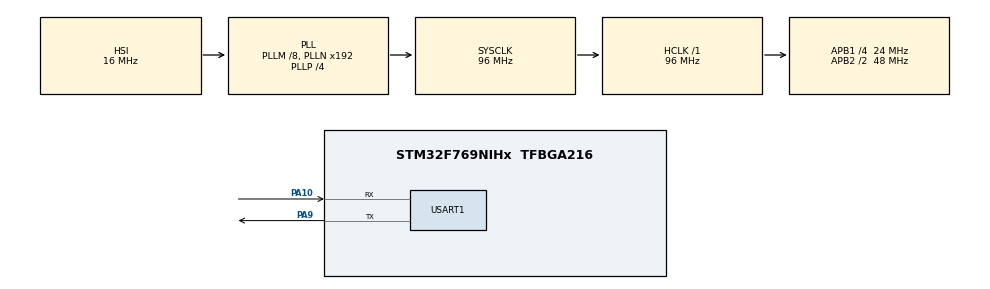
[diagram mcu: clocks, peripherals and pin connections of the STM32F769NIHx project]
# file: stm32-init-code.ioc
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Mcu.Family=STM32F7
Mcu.Name=STM32F769NIHx
Mcu.Package=TFBGA216
NVIC.PriorityGroup=NVIC_PRIORITYGROUP_4
PA10.Mode=Asynchronous
PA10.Signal=USART1_RX
PA9.Mode=Asynchronous
PA9.Signal=USART1_TX
ProjectManager.HeapSize=0x200
ProjectManager.StackSize=0x400
ProjectManager.TargetToolchain=Makefile
RCC.AHBFreq_Value=96000000
RCC.APB1CLKDivider=RCC_HCLK_DIV4
RCC.APB1Freq_Value=24000000
RCC.APB1TimFreq_Value=48000000
RCC.APB2CLKDivider=RCC_HCLK_DIV2
RCC.APB2Freq_Value=48000000
RCC.APB2TimFreq_Value=96000000
RCC.CortexFreq_Value=96000000
RCC.HCLKFreq_Value=96000000
RCC.HSE_VALUE=25000000
RCC.HSI_VALUE=16000000
RCC.LSE_VALUE=32768
RCC.PLLM=8
RCC.PLLP=RCC_PLLP_DIV4
RCC.PLLQ=4
RCC.PLLSAIQ=3
RCC.SYSCLKFreq_VALUE=96000000
RCC.SYSCLKSource=RCC_SYSCLKSOURCE_PLLCLK
RCC.USBFreq_Value=96000000
RCC.VCOOutputFreq_Value=384000000
USART1.VirtualMode-Asynchronous=VM_ASYNC
board=STM32F769I-DISCO

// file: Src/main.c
/* USER CODE BEGIN Header */
/**
  ******************************************************************************
  * @file           : main.c
  * @brief          : Main program body
  ******************************************************************************
  * @attention
  *
  * <h2><center>&copy; Copyright (c) 2021 STMicroelectronics.
  * All rights reserved.</center></h2>
  *
  * This software component is licensed by ST under BSD 3-Clause license,
  * the "License"; You may not use this file except in compliance with the
  * License. You may obtain a copy of the License at:
  *                        opensource.org/licenses/BSD-3-Clause
  *
  ******************************************************************************
  */
/* USER CODE END Header */
#include "main.h"

UART_HandleTypeDef huart1;

void SystemClock_Config(void);
static void MX_GPIO_Init(void);
static void MX_USART1_UART_Init(void);
/* USER CODE BEGIN PFP */
static void flash_invoke_application(uint32_t app_address);
/* USER CODE END PFP */

int main(void)
{
  /* USER CODE BEGIN 1 */
  uint32_t flash_app_address = (uint32_t)0x08010000;
  /* USER CODE END 1 */

  /* MCU Configuration--------------------------------------------------------*/

  /* Reset of all peripherals, Initializes the Flash interface and the Systick. */
  HAL_Init();

  /* Configure the system clock */
  SystemClock_Config();

  /* Initialize all configured peripherals */
  MX_GPIO_Init();
  MX_USART1_UART_Init();
  /* USER CODE BEGIN 2 */
  flash_invoke_application(flash_app_address);
  /* USER CODE END 2 */

  /* Infinite loop */
  while (1)
  {

  }
}

void SystemClock_Config(void)
{
  RCC_OscInitTypeDef RCC_OscInitStruct = {0};
  RCC_ClkInitTypeDef RCC_ClkInitStruct = {0};
  RCC_PeriphCLKInitTypeDef PeriphClkInitStruct = {0};

  /** Configure the main internal regulator output voltage
  */
  __HAL_RCC_PWR_CLK_ENABLE();
  __HAL_PWR_VOLTAGESCALING_CONFIG(PWR_REGULATOR_VOLTAGE_SCALE3);
  /** Initializes the RCC Oscillators according to the specified parameters
  * in the RCC_OscInitTypeDef structure.
  */
  RCC_OscInitStruct.OscillatorType = RCC_OSCILLATORTYPE_HSI;
  RCC_OscInitStruct.HSIState = RCC_HSI_ON;
  RCC_OscInitStruct.HSICalibrationValue = RCC_HSICALIBRATION_DEFAULT;
  RCC_OscInitStruct.PLL.PLLState = RCC_PLL_ON;
  RCC_OscInitStruct.PLL.PLLSource = RCC_PLLSOURCE_HSI;
  RCC_OscInitStruct.PLL.PLLM = 8;
  RCC_OscInitStruct.PLL.PLLN = 192;
  RCC_OscInitStruct.PLL.PLLP = RCC_PLLP_DIV4;
  RCC_OscInitStruct.PLL.PLLQ = 4;
  if (HAL_RCC_OscConfig(&RCC_OscInitStruct) != HAL_OK)
  {
    Error_Handler();
  }
  /** Initializes the CPU, AHB and APB buses clocks
  */
  RCC_ClkInitStruct.ClockType = RCC_CLOCKTYPE_HCLK|RCC_CLOCKTYPE_SYSCLK
                              |RCC_CLOCKTYPE_PCLK1|RCC_CLOCKTYPE_PCLK2;
  RCC_ClkInitStruct.SYSCLKSource = RCC_SYSCLKSOURCE_PLLCLK;
  RCC_ClkInitStruct.AHBCLKDivider = RCC_SYSCLK_DIV1;
  RCC_ClkInitStruct.APB1CLKDivider = RCC_HCLK_DIV4;
  RCC_ClkInitStruct.APB2CLKDivider = RCC_HCLK_DIV2;

  if (HAL_RCC_ClockConfig(&RCC_ClkInitStruct, FLASH_LATENCY_3) != HAL_OK)
  {
    Error_Handler();
  }
  PeriphClkInitStruct.PeriphClockSelection = RCC_PERIPHCLK_USART1;
  PeriphClkInitStruct.Usart1ClockSelection = RCC_USART1CLKSOURCE_PCLK2;
  if (HAL_RCCEx_PeriphCLKConfig(&PeriphClkInitStruct) != HAL_OK)
  {
    Error_Handler();
  }
}

static void MX_USART1_UART_Init(void)
{

  huart1.Instance = USART1;
  huart1.Init.BaudRate = 115200;
  huart1.Init.WordLength = UART_WORDLENGTH_8B;
  huart1.Init.StopBits = UART_STOPBITS_1;
  huart1.Init.Parity = UART_PARITY_NONE;
  huart1.Init.Mode = UART_MODE_TX_RX;
  huart1.Init.HwFlowCtl = UART_HWCONTROL_NONE;
  huart1.Init.OverSampling = UART_OVERSAMPLING_16;
  huart1.Init.OneBitSampling = UART_ONE_BIT_SAMPLE_DISABLE;
  huart1.AdvancedInit.AdvFeatureInit = UART_ADVFEATURE_NO_INIT;
  if (HAL_UART_Init(&huart1) != HAL_OK)
  {
    Error_Handler();
  }

}

static void MX_GPIO_Init(void)
{

  /* GPIO Ports Clock Enable */
  __HAL_RCC_GPIOA_CLK_ENABLE();

}

/* USER CODE BEGIN 4 */
static void flash_invoke_application(uint32_t app_address)
{
	uint32_t msp_value = 0;
	void (*app_reset_handler)(void);

	SysTick->CTRL = 0;
	SysTick->LOAD = 0;
	SysTick->VAL = 0;

	/* Disable all peripherals*/
	HAL_DeInit();

	msp_value = *(__IO uint32_t*)app_address;
	__set_MSP(msp_value);
	uint32_t resethandler_address = *(__IO uint32_t*)(app_address + 0x4);
	app_reset_handler = (void*) resethandler_address;

	app_reset_handler();
}
/* USER CODE END 4 */

void Error_Handler(void)
{
}

/************************ (C) COPYRIGHT STMicroelectronics *****END OF FILE****/
